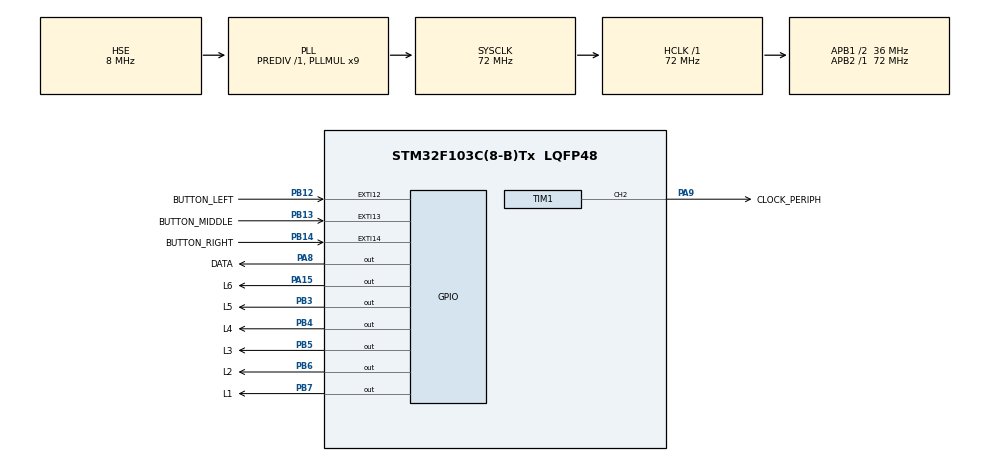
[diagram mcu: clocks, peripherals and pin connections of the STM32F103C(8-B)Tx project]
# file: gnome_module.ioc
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FREERTOS.HEAP_NUMBER=3
FREERTOS.INCLUDE_pcTaskGetTaskName=1
FREERTOS.Tasks01=defaultTask,24,128,StartDefaultTask,Default,NULL,Dynamic,NULL,NULL
FREERTOS.configCHECK_FOR_STACK_OVERFLOW=1
FREERTOS.configMINIMAL_STACK_SIZE=128
FREERTOS.configTIMER_QUEUE_LENGTH=5
FREERTOS.configTIMER_TASK_STACK_DEPTH=128
FREERTOS.configTOTAL_HEAP_SIZE=4352
FREERTOS.configUSE_NEWLIB_REENTRANT=1
Mcu.Family=STM32F1
Mcu.Name=STM32F103C(8-B)Tx
Mcu.Package=LQFP48
NVIC.EXTI15_10_IRQn=true\:5\:0\:false\:false\:true\:true\:true\:true\:true
NVIC.PriorityGroup=NVIC_PRIORITYGROUP_4
NVIC.TIM1_UP_IRQn=true\:5\:0\:false\:false\:true\:true\:true\:true\:true
NVIC.TIM4_IRQn=true\:15\:0\:false\:false\:true\:false\:false\:true\:true
NVIC.TimeBase=TIM4_IRQn
NVIC.TimeBaseIP=TIM4
PA13.Mode=Serial_Wire
PA13.Signal=SYS_JTMS-SWDIO
PA14.Mode=Serial_Wire
PA14.Signal=SYS_JTCK-SWCLK
PA15.GPIO_Label=L6
PA15.GPIO_ModeDefaultOutputPP=GPIO_MODE_OUTPUT_PP
PA15.GPIO_PuPd=GPIO_NOPULL
PA15.GPIO_Speed=GPIO_SPEED_FREQ_HIGH
PA15.PinState=GPIO_PIN_RESET
PA15.Signal=GPIO_Output
PA8.GPIO_Label=DATA
PA8.GPIO_PuPd=GPIO_NOPULL
PA8.GPIO_Speed=GPIO_SPEED_FREQ_HIGH
PA8.PinState=GPIO_PIN_SET
PA8.Signal=GPIO_Output
PA9.GPIO_Label=CLOCK_PERIPH
PA9.Signal=S_TIM1_CH2
PB12.GPIO_Label=BUTTON_LEFT
PB12.GPIO_ModeDefaultEXTI=GPIO_MODE_IT_RISING_FALLING
PB12.Signal=GPXTI12
PB13.GPIO_Label=BUTTON_MIDDLE
PB13.GPIO_ModeDefaultEXTI=GPIO_MODE_IT_FALLING
PB13.Signal=GPXTI13
PB14.GPIO_Label=BUTTON_RIGHT
PB14.GPIO_ModeDefaultEXTI=GPIO_MODE_IT_RISING_FALLING
PB14.Signal=GPXTI14
PB3.GPIO_Label=L5
PB3.GPIO_Speed=GPIO_SPEED_FREQ_HIGH
PB3.PinState=GPIO_PIN_RESET
PB3.Signal=GPIO_Output
PB4.GPIO_Label=L4
PB4.GPIO_Speed=GPIO_SPEED_FREQ_HIGH
PB4.PinState=GPIO_PIN_RESET
PB4.Signal=GPIO_Output
PB5.GPIO_Label=L3
PB5.GPIO_Speed=GPIO_SPEED_FREQ_HIGH
PB5.PinState=GPIO_PIN_RESET
PB5.Signal=GPIO_Output
PB6.GPIO_Label=L2
PB6.GPIO_Speed=GPIO_SPEED_FREQ_HIGH
PB6.PinState=GPIO_PIN_RESET
PB6.Signal=GPIO_Output
PB7.GPIO_Label=L1
PB7.GPIO_Speed=GPIO_SPEED_FREQ_HIGH
PB7.PinState=GPIO_PIN_RESET
PB7.Signal=GPIO_Output
PD0-OSC_IN.Mode=HSE-External-Oscillator
PD0-OSC_IN.Signal=RCC_OSC_IN
PD1-OSC_OUT.Mode=HSE-External-Oscillator
PD1-OSC_OUT.Signal=RCC_OSC_OUT
ProjectManager.HeapSize=0x700
ProjectManager.StackSize=0x200
ProjectManager.TargetToolchain=STM32CubeIDE
RCC.ADCPresc=RCC_ADCPCLK2_DIV6
RCC.AHBFreq_Value=72000000
RCC.APB1CLKDivider=RCC_HCLK_DIV2
RCC.APB1Freq_Value=36000000
RCC.APB1TimFreq_Value=72000000
RCC.APB2Freq_Value=72000000
RCC.APB2TimFreq_Value=72000000
RCC.HCLKFreq_Value=72000000
RCC.PLLMUL=RCC_PLL_MUL9
RCC.PLLSourceVirtual=RCC_PLLSOURCE_HSE
RCC.SYSCLKFreq_VALUE=72000000
RCC.SYSCLKSource=RCC_SYSCLKSOURCE_PLLCLK
RCC.USBFreq_Value=48000000
RCC.USBPrescaler=RCC_USBCLKSOURCE_PLL_DIV1_5
SH.S_TIM1_CH2.0=TIM1_CH2,PWM Generation2 CH2
TIM1.Channel-PWM\ Generation2\ CH2=TIM_CHANNEL_2
TIM1.Period=1000-1
TIM1.Prescaler=90-1
VP_FREERTOS_VS_CMSIS_V2.Mode=CMSIS_V2
VP_RTC_VS_RTC_Activate.Mode=RTC_Enabled
VP_RTC_VS_RTC_Calendar.Mode=RTC_Calendar
VP_SYS_VS_tim4.Mode=TIM4
VP_TIM1_VS_ClockSourceINT.Mode=Internal
board=custom

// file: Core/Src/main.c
/* USER CODE BEGIN Header */
/**
  ******************************************************************************
  * @file           : main.c
  * @brief          : Main program body
  ******************************************************************************
  * @attention
  *
  * Copyright (c) 2022 STMicroelectronics.
  * All rights reserved.
  *
  * This software is licensed under terms that can be found in the LICENSE file
  * in the root directory of this software component.
  * If no LICENSE file comes with this software, it is provided AS-IS.
  *
  ******************************************************************************
  */
/* USER CODE END Header */
#include "main.h"
#include "cmsis_os.h"
#include "rtc.h"
#include "tim.h"
#include "gpio.h"

/* USER CODE BEGIN PV */

int g_bit = 0;
/* USER CODE END PV */

void SystemClock_Config(void);
void MX_FREERTOS_Init(void);

int main(void)
{

  /* MCU Configuration--------------------------------------------------------*/

  /* Reset of all peripherals, Initializes the Flash interface and the Systick. */
  HAL_Init();

  /* Configure the system clock */
  SystemClock_Config();

  /* Initialize all configured peripherals */
  MX_GPIO_Init();
  MX_TIM1_Init();
  MX_RTC_Init();
  /* USER CODE BEGIN 2 */

  HAL_TIM_Base_Start_IT(&htim1);
  /* USER CODE END 2 */

  /* Init scheduler */
  osKernelInitialize();  /* Call init function for freertos objects (in freertos.c) */
  MX_FREERTOS_Init();

  /* Start scheduler */
  osKernelStart();

  /* We should never get here as control is now taken by the scheduler */
  /* Infinite loop */
  while (1)
  {

  }
}

void SystemClock_Config(void)
{
  RCC_OscInitTypeDef RCC_OscInitStruct = {0};
  RCC_ClkInitTypeDef RCC_ClkInitStruct = {0};
  RCC_PeriphCLKInitTypeDef PeriphClkInit = {0};

  /** Initializes the RCC Oscillators according to the specified parameters
  * in the RCC_OscInitTypeDef structure.
  */
  RCC_OscInitStruct.OscillatorType = RCC_OSCILLATORTYPE_LSI|RCC_OSCILLATORTYPE_HSE;
  RCC_OscInitStruct.HSEState = RCC_HSE_ON;
  RCC_OscInitStruct.HSEPredivValue = RCC_HSE_PREDIV_DIV1;
  RCC_OscInitStruct.HSIState = RCC_HSI_ON;
  RCC_OscInitStruct.LSIState = RCC_LSI_ON;
  RCC_OscInitStruct.PLL.PLLState = RCC_PLL_ON;
  RCC_OscInitStruct.PLL.PLLSource = RCC_PLLSOURCE_HSE;
  RCC_OscInitStruct.PLL.PLLMUL = RCC_PLL_MUL9;
  if (HAL_RCC_OscConfig(&RCC_OscInitStruct) != HAL_OK)
  {
    Error_Handler();
  }

  /** Initializes the CPU, AHB and APB buses clocks
  */
  RCC_ClkInitStruct.ClockType = RCC_CLOCKTYPE_HCLK|RCC_CLOCKTYPE_SYSCLK
                              |RCC_CLOCKTYPE_PCLK1|RCC_CLOCKTYPE_PCLK2;
  RCC_ClkInitStruct.SYSCLKSource = RCC_SYSCLKSOURCE_PLLCLK;
  RCC_ClkInitStruct.AHBCLKDivider = RCC_SYSCLK_DIV1;
  RCC_ClkInitStruct.APB1CLKDivider = RCC_HCLK_DIV2;
  RCC_ClkInitStruct.APB2CLKDivider = RCC_HCLK_DIV1;

  if (HAL_RCC_ClockConfig(&RCC_ClkInitStruct, FLASH_LATENCY_2) != HAL_OK)
  {
    Error_Handler();
  }
  PeriphClkInit.PeriphClockSelection = RCC_PERIPHCLK_RTC;
  PeriphClkInit.RTCClockSelection = RCC_RTCCLKSOURCE_LSI;
  if (HAL_RCCEx_PeriphCLKConfig(&PeriphClkInit) != HAL_OK)
  {
    Error_Handler();
  }
}

void HAL_TIM_PeriodElapsedCallback(TIM_HandleTypeDef *htim)
{
  if (htim->Instance == TIM4) {
    HAL_IncTick();
  }
  /* USER CODE BEGIN Callback 1 */
  if (htim->Instance == TIM1) {
    if(g_bit < 11){
    	g_bit++;
    }
    else {
    	g_bit = 0;
    }
    clockControl();
  }

  /* USER CODE END Callback 1 */
}

void Error_Handler(void)
{
  __disable_irq();
  while (1)
  {
  }
}

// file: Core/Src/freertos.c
/* USER CODE BEGIN Header */
/**
  ******************************************************************************
  * File Name          : freertos.c
  * Description        : Code for freertos applications
  ******************************************************************************
  * @attention
  *
  * Copyright (c) 2022 STMicroelectronics.
  * All rights reserved.
  *
  * This software is licensed under terms that can be found in the LICENSE file
  * in the root directory of this software component.
  * If no LICENSE file comes with this software, it is provided AS-IS.
  *
  ******************************************************************************
  */
/* USER CODE END Header */

#include "FreeRTOS.h"
#include "task.h"
#include "main.h"
#include "cmsis_os.h"

/* USER CODE BEGIN Includes */
#include "d_main.h"
/* USER CODE END Includes */

/* Definitions for defaultTask */
osThreadId_t defaultTaskHandle;
const osThreadAttr_t defaultTask_attributes = {
  .name = "defaultTask",
  .stack_size = 128 * 4,
  .priority = (osPriority_t) osPriorityNormal,
};

void StartDefaultTask(void *argument);

void MX_FREERTOS_Init(void); /* (MISRA C 2004 rule 8.1) */

/* Hook prototypes */
void vApplicationStackOverflowHook(xTaskHandle xTask, signed char *pcTaskName);

/* USER CODE BEGIN 4 */
void vApplicationStackOverflowHook(xTaskHandle xTask, signed char *pcTaskName)
{
   /* Run time stack overflow checking is performed if
   configCHECK_FOR_STACK_OVERFLOW is defined to 1 or 2. This hook function is
   called if a stack overflow is detected. */
}
/* USER CODE END 4 */

void MX_FREERTOS_Init(void) {

  /* Create the thread(s) */
  /* creation of defaultTask */
  defaultTaskHandle = osThreadNew(StartDefaultTask, NULL, &defaultTask_attributes);

}

void StartDefaultTask(void *argument)
{
  /* USER CODE BEGIN StartDefaultTask */
  d_main();
  /* USER CODE END StartDefaultTask */
}
